# STM32H743 register map
File version: 2.4
CPU: CM7 r0p1, little endian, MPU, FPU, 4 interrupt priority bits
Registers are 32-bit, read-write, reset 0x0 unless marked. A register's access mark holds for its fields unless they carry their own. Offsets are from the block's base; [hi:lo] are bit positions; {n}, {i} and the like mark numbered series.

## I2C1 — I2C 总线接口
Base 0x40005400
Same registers: I2C2 0x40005800, I2C3 0x40005C00, I2C4 0x58001C00
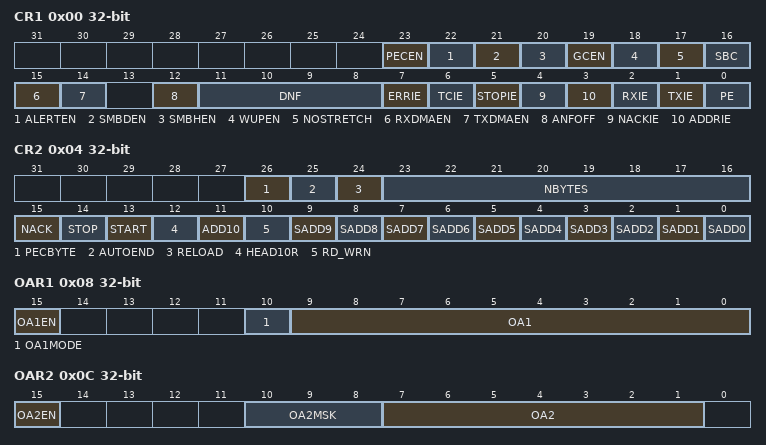
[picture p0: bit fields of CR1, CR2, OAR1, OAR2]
0x00 CR1 — 访问：无等待状态，但对本寄存器的写访问正在进行时再次发起写访问的情况除外。此时，第二次写访问会插入等待状态，直到前一次写操作完成。第二次写访问的延迟最长可达 2 个 PCLK1 周期 + 6 个 I2CCLK 周期。
  [23] PECEN — PEC 使能。注意：若器件不支持 SMBus 功能，此位为保留位，由硬件强制置 0。请参见第 25.3 节：I2C 实现。
  [22] ALERTEN — SMBus 报警使能。设备模式（SMBHEN=0）：……主机模式（SMBHEN=1）：……注意：当 ALERTEN=0 时，SMBA 引脚可用作标准 GPIO。若器件不支持 SMBus 功能，此位为保留位，由硬件强制置 0。请参见第 25.3 节：I2C 实现。
  [21] SMBDEN — SMBus 设备默认地址使能。注意：若器件不支持 SMBus 功能，此位为保留位，由硬件强制置 0。请参见第 25.3 节：I2C 实现。
  [20] SMBHEN — SMBus 主机地址使能。注意：若器件不支持 SMBus 功能，此位为保留位，由硬件强制置 0。请参见第 25.3 节：I2C 实现。
  [19] GCEN — 通用广播使能
  [18] WUPEN — 停止模式唤醒使能。注意：若器件不支持从停止模式唤醒，此位为保留位，由硬件强制置 0。请参见第 25.3 节：I2C 实现。注意：WUPEN 仅可在 DNF=0000 时置位。
  [17] NOSTRETCH — 时钟拉伸禁用。此位用于在从机模式下禁用时钟拉伸。主机模式下必须保持清零。注意：此位仅可在 I2C 禁用（PE=0）时编程。
  [16] SBC — 从机字节控制。此位用于在从机模式下使能硬件字节控制。
  [15] RXDMAEN — DMA 接收请求使能
  [14] TXDMAEN — DMA 发送请求使能
  [12] ANFOFF — 模拟噪声滤波器关闭。注意：此位仅可在 I2C 禁用（PE=0）时编程。
  [11:8] DNF — 数字噪声滤波器。这些位用于配置 SDA 和 SCL 输入端的数字噪声滤波器。数字滤波器可滤除宽度不超过 DNF[3:0] × tI2CCLK 的毛刺……注意：若模拟滤波器也使能，则数字滤波器叠加在模拟滤波器之上。此滤波器仅可在 I2C 禁用（PE=0）时编程。
  [7] ERRIE — 错误中断使能。注意：以下任一错误均会产生中断：仲裁丢失（ARLO）、总线错误检测（BERR）、上溢/下溢（OVR）、超时检测（TIMEOUT）、PEC 错误检测（PECERR）、SMBus 报警引脚事件检测（ALERT）。
  [6] TCIE — 传输完成中断使能。注意：以下任一事件均会产生中断：传输完成（TC）、传输完成重载（TCR）。
  [5] STOPIE — STOP 检测中断使能
  [4] NACKIE — 接收到非应答中断使能
  [3] ADDRIE — 地址匹配中断使能（仅从机模式）
  [2] RXIE — 接收中断使能
  [1] TXIE — 发送中断使能
  [0] PE — 外设使能。注意：当 PE=0 时，I2C 的 SCL 和 SDA 线将被释放，内部状态机和状态位恢复为复位值。清零 PE 后，必须保持低电平至少 3 个 APB 时钟周期。
0x04 CR2 — 访问：无等待状态，但对本寄存器的写访问正在进行时再次发起写访问的情况除外。此时，第二次写访问会插入等待状态，直到前一次写操作完成。第二次写访问的延迟最长可达 2 个 PCLK1 周期 + 6 个 I2CCLK 周期。
  [26] PECBYTE — 数据包错误校验字节。此位由软件置位，在 PEC 传输完成、收到 STOP 条件或地址匹配事件时、或 PE=0 时由硬件清零。注意：对此位写 0 无效。此位在 RELOAD 置位时无效。此位在从机模式且 SBC=0 时无效。若器件不支持 SMBus 功能，此位为保留位，由硬件强制置 0。请参见第 25.3 节：I2C 实现。
  [25] AUTOEND — 自动结束模式（主机模式）。此位由软件置位和清零。注意：此位在从机模式或 RELOAD 位置位时无效。
  [24] RELOAD — NBYTES 重载模式。此位由软件置位和清零。
  [23:16] NBYTES — 字节数。在此编入待发送/接收的字节数。在从机模式且 SBC=0 时此字段为无关位。注意：START 位置位期间不允许更改这些位。
  [15] NACK — NACK 生成（从机模式）。此位由软件置位，在 NACK 发送后、收到 STOP 条件或地址匹配事件时、或 PE=0 时由硬件清零。注意：对此位写 0 无效。此位仅用于从机模式：在主机接收模式下，无论 NACK 位为何值，硬件都会在 STOP 或 RESTART 条件前的最后一个字节之后自动生成 NACK。在从机接收 NOSTRETCH 模式下发生上溢时，无论 NACK 位为何值，均自动生成 NACK。当硬件 PEC 校验使能（PECBYTE=1）时，PEC 应答值不依赖于 NACK 的值。
  [14] STOP — 停止条件生成（主机模式）。此位由软件置位，在检测到停止条件时或 PE=0 时由硬件清零。主机模式下：……注意：对此位写 0 无效。
  [13] START — 起始条件生成。此位由软件置位，由硬件在 Start 信号及随后的地址序列发送完成后、发生仲裁丢失时、检测到超时错误时或 PE=0 时清零。也可以通过软件对 I2C_ICR 寄存器的 ADDRCF 位写 1 来清零。若 I2C 已处于主机模式且 AUTOEND=0，当 RELOAD=0 时，置位此位将在 NBYTES 传输结束后生成重复起始条件（Repeated Start）。否则，置位此位将在总线空闲后生成一个起始条件（START）。注意：对此位写 0 无效。即使总线处于 BUSY 状态或 I2C 处于从机模式，亦可置位 START 位。RELOAD 置位时此位无效。
  [12] HEAD10R — 10 位地址仅读取报头方向（主机接收模式）。注意：START 位置位期间不允许更改此位。
  [11] ADD10 — 10 位地址模式（主机模式）。注意：START 位置位期间不允许更改此位。
  [10] RD_WRN — 传输方向（主机模式）。注意：START 位置位期间不允许更改此位。
  [9] SADD9 — 从机地址位 9:8（主机模式）。7 位地址模式（ADD10=0）：这些位为无关位。10 位地址模式（ADD10=1）：这些位应写入待发送从机地址的位 9:8。注意：START 位置位期间不允许更改这些位。
  [8] SADD8 — 从机地址位 9:8（主机模式）。7 位地址模式（ADD10=0）：这些位为无关位。10 位地址模式（ADD10=1）：这些位应写入待发送从机地址的位 9:8。注意：START 位置位期间不允许更改这些位。
  [n] SADD{n} (n=1..7) — 从机地址位 7:1（主机模式）。7 位地址模式（ADD10=0）：这些位应写入待发送的 7 位从机地址。10 位地址模式（ADD10=1）：这些位应写入待发送从机地址的位 7:1。注意：START 位置位期间不允许更改这些位。
  [0] SADD0 — 从机地址位 0（主机模式）。7 位地址模式（ADD10=0）：此位为无关位。10 位地址模式（ADD10=1）：此位应写入待发送从机地址的位 0。注意：START 位置位期间不允许更改这些位。
0x08 OAR1 — 访问：无等待状态，但对本寄存器的写访问正在进行时再次发起写访问的情况除外。此时，第二次写访问会插入等待状态，直到前一次写操作完成。第二次写访问的延迟最长可达 2 个 PCLK1 周期 + 6 个 I2CCLK 周期。
  [15] OA1EN — 自身地址 1 使能
  [10] OA1MODE — 自身地址 1 的 10 位模式。注意：此位仅可在 OA1EN=0 时写入。
  [9:0] OA1 — 接口地址。7 位地址模式：无关位。10 位地址模式：地址的位 9:8。注意：这些位仅可在 OA1EN=0 时写入。OA1[7:1]：接口地址的位 7:1。注意：这些位仅可在 OA1EN=0 时写入。OA1[0]：接口地址。7 位地址模式：无关位。10 位地址模式：地址的位 0。注意：此位仅可在 OA1EN=0 时写入。
0x0C OAR2 — 访问：无等待状态，但对本寄存器的写访问正在进行时再次发起写访问的情况除外。此时，第二次写访问会插入等待状态，直到前一次写操作完成。第二次写访问的延迟最长可达 2 个 PCLK1 周期 + 6 个 I2CCLK 周期。
  [15] OA2EN — 自身地址 2 使能
  [10:8] OA2MSK — 自身地址 2 掩码。注意：这些位仅可在 OA2EN=0 时写入。一旦 OA2MSK 不等于 0，即使比较匹配，保留的 I2C 地址（0b0000xxx 和 0b1111xxx）也不会被应答。
  [7:1] OA2 — 接口地址的位 7:1。注意：这些位仅可在 OA2EN=0 时写入。
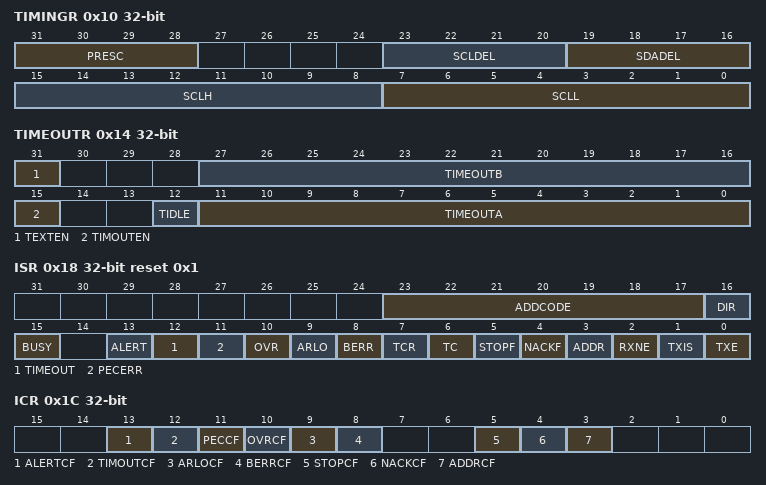
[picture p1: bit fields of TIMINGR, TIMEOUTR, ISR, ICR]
0x10 TIMINGR — 访问：无等待状态
  [31:28] PRESC — 时序预分频器。此字段用于对 I2CCLK 进行预分频，以生成时钟周期 tPRESC，供数据建立和保持计数器（参见第 9 页的 I2C 时序）以及 SCL 高、低电平计数器（参见第 24 页的 I2C 主机初始化）使用。tPRESC = (PRESC + 1) × tI2CCLK
  [23:20] SCLDEL — 数据建立时间。此字段用于生成 SDA 边沿与 SCL 上升沿之间的延迟 tSCLDEL。在主机模式以及 NOSTRETCH=0 的从机模式下，SCL 线在 tSCLDEL 期间被拉低。tSCLDEL = (SCLDEL + 1) × tPRESC。注意：tSCLDEL 用于生成 tSU:DAT 时序。
  [19:16] SDADEL — 数据保持时间。此字段用于生成 SCL 下降沿与 SDA 边沿之间的延迟 tSDADEL。在主机模式以及 NOSTRETCH=0 的从机模式下，SCL 线在 tSDADEL 期间被拉低。tSDADEL = SDADEL × tPRESC。注意：SDADEL 用于生成 tHD:DAT 时序。
  [15:8] SCLH — SCL 高电平周期（主机模式）。此字段用于在主机模式下生成 SCL 高电平周期。tSCLH = (SCLH + 1) × tPRESC。注意：SCLH 也用于生成 tSU:STO 和 tHD:STA 时序。
  [7:0] SCLL — SCL 低电平周期（主机模式）。此字段用于在主机模式下生成 SCL 低电平周期。tSCLL = (SCLL + 1) × tPRESC。注意：SCLL 也用于生成 tBUF 和 tSU:STA 时序。
0x14 TIMEOUTR — 访问：无等待状态，但对本寄存器的写访问正在进行时再次发起写访问的情况除外。此时，第二次写访问会插入等待状态，直到前一次写操作完成。第二次写访问的延迟最长可达 2 个 PCLK1 周期 + 6 个 I2CCLK 周期。
  [31] TEXTEN — 扩展时钟超时使能
  [27:16] TIMEOUTB — 总线超时 B。此字段用于配置累积时钟扩展超时：在主机模式下，检测主机累积时钟低电平扩展时间（tLOW:MEXT）；在从机模式下，检测从机累积时钟低电平扩展时间（tLOW:SEXT）。tLOW:EXT = (TIMEOUTB + 1) × 2048 × tI2CCLK。注意：这些位仅可在 TEXTEN=0 时写入。
  [15] TIMOUTEN — 时钟超时使能
  [12] TIDLE — 空闲时钟超时检测。注意：此位仅可在 TIMOUTEN=0 时写入。
  [11:0] TIMEOUTA — 总线超时 A。此字段用于配置：当 TIDLE=0 时，SCL 低电平超时条件 tTIMEOUT。tTIMEOUT = (TIMEOUTA + 1) × 2048 × tI2CCLK。当 TIDLE=1 时，总线空闲条件（SCL 和 SDA 均为高电平）。tIDLE = (TIMEOUTA + 1) × 4 × tI2CCLK。注意：这些位仅可在 TIMOUTEN=0 时写入。
0x18 ISR access per field reset 0x1 — 访问：无等待状态
  [23:17] ADDCODE ro — 地址匹配码（从机模式）。发生地址匹配事件（ADDR=1）时，这些位更新为接收到的地址。在 10 位地址情况下，ADDCODE 提供 10 位报头，后跟地址的 2 个最高有效位。
  [16] DIR ro — 传输方向（从机模式）。发生地址匹配事件（ADDR=1）时更新此标志。
  [15] BUSY ro — 总线忙碌。此标志指示总线上正在进行通信。检测到起始条件时此位由硬件置位。检测到停止条件或 PE=0 时由硬件清零。
  [13] ALERT ro — SMBus 报警。当 SMBHEN=1（SMBus 主机配置）、ALERTEN=1 且 SMBA 引脚上检测到 SMBALERT 事件（下降沿）时，此位由硬件置位。通过软件将 ALERTCF 位置位来清零。注意：PE=0 时此位由硬件清零。若器件不支持 SMBus 功能，此位为保留位，由硬件强制置 0。请参见第 25.3 节：I2C 实现。
  [12] TIMEOUT ro — 超时或 tLOW 检测标志。发生超时或扩展时钟超时时此位由硬件置位。通过软件将 TIMEOUTCF 位置位来清零。注意：PE=0 时此位由硬件清零。若器件不支持 SMBus 功能，此位为保留位，由硬件强制置 0。请参见第 25.3 节：I2C 实现。
  [11] PECERR ro — 接收 PEC 错误。当接收到的 PEC 与 PEC 寄存器内容不匹配时，此位由硬件置位。在接收到错误的 PEC 后自动发送 NACK。通过软件将 PECCF 位置位来清零。注意：PE=0 时此位由硬件清零。若器件不支持 SMBus 功能，此位为保留位，由硬件强制置 0。请参见第 25.3 节：I2C 实现。
  [10] OVR ro — 上溢/下溢（从机模式）。在 NOSTRETCH=1 的从机模式下，当发生上溢/下溢错误时此位由硬件置位。通过软件将 OVRCF 位置位来清零。注意：PE=0 时此位由硬件清零。
  [9] ARLO ro — 仲裁丢失。发生仲裁丢失时此位由硬件置位。通过软件将 ARLOCF 位置位来清零。注意：PE=0 时此位由硬件清零。
  [8] BERR ro — 总线错误。当本外设参与传输期间检测到异常的起始或停止条件时，此位由硬件置位。从机模式下地址阶段期间不会置位此标志。通过软件将 BERRCF 位置位来清零。注意：PE=0 时此位由硬件清零。
  [7] TCR ro — 传输完成重载。当 RELOAD=1 且 NBYTES 字节的数据已完成传输时，此位由硬件置位。当 NBYTES 被写入非零值时由软件清零。注意：PE=0 时此位由硬件清零。此标志仅适用于主机模式，或 SBC 位置位的从机模式。
  [6] TC ro — 传输完成（主机模式）。当 RELOAD=0、AUTOEND=0 且 NBYTES 字节的数据已完成传输时，此位由硬件置位。当 START 位或 STOP 位置位时由软件清零。注意：PE=0 时此位由硬件清零。
  [5] STOPF ro — 停止条件检测标志。当总线上检测到停止条件且本外设参与了此次传输时，此位由硬件置位：作为主机——前提是停止条件由本外设生成；或作为从机——前提是本外设在此次传输中先前已被寻址。通过软件将 STOPCF 位置位来清零。注意：PE=0 时此位由硬件清零。
  [4] NACKF ro — 接收到非应答标志。当在字节传输后接收到 NACK 时，此位由硬件置位。通过软件将 NACKCF 位置位来清零。注意：PE=0 时此位由硬件清零。
  [3] ADDR ro — 地址匹配（从机模式）。当接收到的从机地址与任一已使能的从机地址匹配时，此位由硬件置位。通过软件将 ADDRCF 位置位来清零。注意：PE=0 时此位由硬件清零。
  [2] RXNE ro — 接收数据寄存器非空（接收器）。当接收到的数据被复制到 I2C_RXDR 寄存器且可供读取时，此位由硬件置位。读取 I2C_RXDR 后此位清零。注意：PE=0 时此位由硬件清零。
  [1] TXIS rw — 发送中断状态（发送器）。当 I2C_TXDR 寄存器为空且待发送数据必须写入 I2C_TXDR 寄存器时，此位由硬件置位。当下一待发送数据写入 I2C_TXDR 寄存器时，此位清零。仅当 NOSTRETCH=1 时，软件可对此位写 1，以生成 TXIS 事件（若 TXIE=1 则产生中断，若 TXDMAEN=1 则产生 DMA 请求）。注意：PE=0 时此位由硬件清零。
  [0] TXE rw — 发送数据寄存器空（发送器）。当 I2C_TXDR 寄存器为空时，此位由硬件置位。当下一待发送数据写入 I2C_TXDR 寄存器时，此位清零。软件可对此位写 1 以清空发送数据寄存器 I2C_TXDR。注意：PE=0 时此位由硬件置位。
0x1C ICR wo — 访问：无等待状态
  [13] ALERTCF — 报警标志清零。对此位写 1 可清零 I2C_ISR 寄存器中的 ALERT 标志。注意：若器件不支持 SMBus 功能，此位为保留位，由硬件强制置 0。请参见第 25.3 节：I2C 实现。
  [12] TIMOUTCF — 超时检测标志清零。对此位写 1 可清零 I2C_ISR 寄存器中的 TIMEOUT 标志。注意：若器件不支持 SMBus 功能，此位为保留位，由硬件强制置 0。请参见第 25.3 节：I2C 实现。
  [11] PECCF — PEC 错误标志清零。对此位写 1 可清零 I2C_ISR 寄存器中的 PECERR 标志。注意：若器件不支持 SMBus 功能，此位为保留位，由硬件强制置 0。请参见第 25.3 节：I2C 实现。
  [10] OVRCF — 上溢/下溢标志清零。对此位写 1 可清零 I2C_ISR 寄存器中的 OVR 标志。
  [9] ARLOCF — 仲裁丢失标志清零。对此位写 1 可清零 I2C_ISR 寄存器中的 ARLO 标志。
  [8] BERRCF — 总线错误标志清零。对此位写 1 可清零 I2C_ISR 寄存器中的 BERRF 标志。
  [5] STOPCF — 停止检测标志清零。对此位写 1 可清零 I2C_ISR 寄存器中的 STOPF 标志。
  [4] NACKCF — 非应答标志清零。对此位写 1 可清零 I2C_ISR 寄存器中的 ACKF 标志。
  [3] ADDRCF — 地址匹配标志清零。对此位写 1 可清零 I2C_ISR 寄存器中的 ADDR 标志。对此位写 1 同时也会清零 I2C_CR2 寄存器中的 START 位。
0x20 PECR ro — 访问：无等待状态
  [7:0] PEC — 数据包错误校验寄存器。当 PECEN=1 时，此字段包含内部 PEC 值。PE=0 时 PEC 由硬件清零。
0x24 RXDR ro — 访问：无等待状态
  [7:0] RXDATA — 8 位接收数据。从 I2C 总线接收到的数据字节。
0x28 TXDR — 访问：无等待状态
  [7:0] TXDATA — 8 位发送数据。待发送到 I2C 总线的数据字节。注意：这些位仅可在 TXE=1 时写入。
